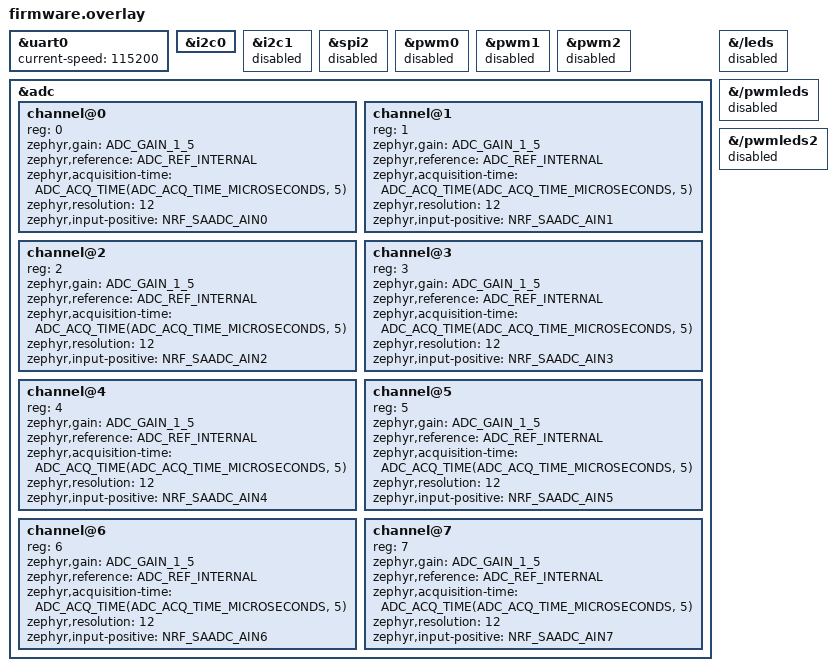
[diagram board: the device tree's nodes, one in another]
&uart0 {
    current-speed = <115200>;
    status = "okay";
};

&i2c0 {
    status = "okay";
};

&i2c1 {
    status = "disabled";
};

&spi2 {
    status = "disabled";
};

&pwm0 {
    status = "disabled";
};

&pwm1 {
    status = "disabled";
};

&pwm2 {
    status = "disabled";
};

&adc {
    status = "okay";
    #address-cells = <1>;
    #size-cells = <0>;

    channel@0 {
        reg = <0>;
        zephyr,gain = "ADC_GAIN_1_5";
        zephyr,reference = "ADC_REF_INTERNAL";
        zephyr,acquisition-time = <ADC_ACQ_TIME(ADC_ACQ_TIME_MICROSECONDS, 5)>;
        zephyr,resolution = <12>;
        zephyr,input-positive = <NRF_SAADC_AIN0>;
    };

    channel@1 {
        reg = <1>;
        zephyr,gain = "ADC_GAIN_1_5";
        zephyr,reference = "ADC_REF_INTERNAL";
        zephyr,acquisition-time = <ADC_ACQ_TIME(ADC_ACQ_TIME_MICROSECONDS, 5)>;
        zephyr,resolution = <12>;
        zephyr,input-positive = <NRF_SAADC_AIN1>;
    };

    channel@2 {
        reg = <2>;
        zephyr,gain = "ADC_GAIN_1_5";
        zephyr,reference = "ADC_REF_INTERNAL";
        zephyr,acquisition-time = <ADC_ACQ_TIME(ADC_ACQ_TIME_MICROSECONDS, 5)>;
        zephyr,resolution = <12>;
        zephyr,input-positive = <NRF_SAADC_AIN2>;
    };

    channel@3 {
        reg = <3>;
        zephyr,gain = "ADC_GAIN_1_5";
        zephyr,reference = "ADC_REF_INTERNAL";
        zephyr,acquisition-time = <ADC_ACQ_TIME(ADC_ACQ_TIME_MICROSECONDS, 5)>;
        zephyr,resolution = <12>;
        zephyr,input-positive = <NRF_SAADC_AIN3>;
    };

    channel@4 {
        reg = <4>;
        zephyr,gain = "ADC_GAIN_1_5";
        zephyr,reference = "ADC_REF_INTERNAL";
        zephyr,acquisition-time = <ADC_ACQ_TIME(ADC_ACQ_TIME_MICROSECONDS, 5)>;
        zephyr,resolution = <12>;
        zephyr,input-positive = <NRF_SAADC_AIN4>;
    };

    channel@5 {
        reg = <5>;
        zephyr,gain = "ADC_GAIN_1_5";
        zephyr,reference = "ADC_REF_INTERNAL";
        zephyr,acquisition-time = <ADC_ACQ_TIME(ADC_ACQ_TIME_MICROSECONDS, 5)>;
        zephyr,resolution = <12>;
        zephyr,input-positive = <NRF_SAADC_AIN5>;
    };

    channel@6 {
        reg = <6>;
        zephyr,gain = "ADC_GAIN_1_5";
        zephyr,reference = "ADC_REF_INTERNAL";
        zephyr,acquisition-time = <ADC_ACQ_TIME(ADC_ACQ_TIME_MICROSECONDS, 5)>;
        zephyr,resolution = <12>;
        zephyr,input-positive = <NRF_SAADC_AIN6>;
    };

    channel@7 {
        reg = <7>;
        zephyr,gain = "ADC_GAIN_1_5";
        zephyr,reference = "ADC_REF_INTERNAL";
        zephyr,acquisition-time = <ADC_ACQ_TIME(ADC_ACQ_TIME_MICROSECONDS, 5)>;
        zephyr,resolution = <12>;
        zephyr,input-positive = <NRF_SAADC_AIN7>;
    };
};

&{/leds} {
    status = "disabled";
};

&{/pwmleds} {
    status = "disabled";
};

&{/pwmleds2} {
    status = "disabled";
};
